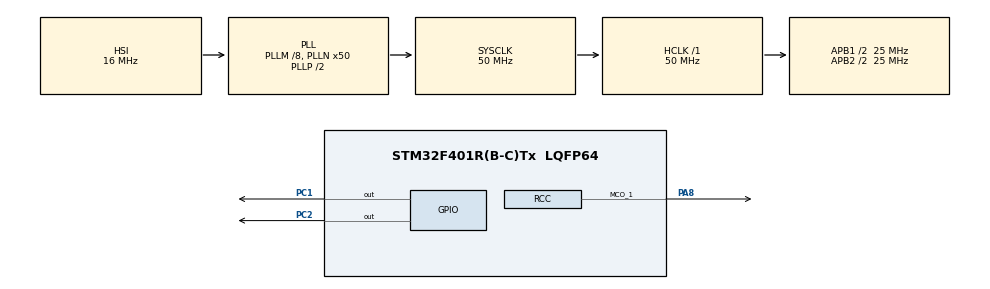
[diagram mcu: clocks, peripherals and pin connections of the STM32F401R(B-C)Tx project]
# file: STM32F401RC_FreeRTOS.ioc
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Mcu.Family=STM32F4
Mcu.Name=STM32F401R(B-C)Tx
Mcu.Package=LQFP64
NVIC.PriorityGroup=NVIC_PRIORITYGROUP_4
NVIC.TIM1_TRG_COM_TIM11_IRQn=true\:15\:0\:false\:false\:true\:false\:true\:true
NVIC.TIM1_UP_TIM10_IRQn=true\:0\:0\:false\:true\:true\:1\:true\:true\:true
NVIC.TimeBase=TIM1_TRG_COM_TIM11_IRQn
NVIC.TimeBaseIP=TIM11
PA8.Mode=Clock-out-1
PA8.Signal=RCC_MCO_1
PC1.GPIO_Speed=GPIO_SPEED_FREQ_VERY_HIGH
PC1.Signal=GPIO_Output
PC2.GPIO_Speed=GPIO_SPEED_FREQ_VERY_HIGH
PC2.Signal=GPIO_Output
PH0\ -\ OSC_IN.Mode=HSE-External-Oscillator
PH0\ -\ OSC_IN.Signal=RCC_OSC_IN
PH1\ -\ OSC_OUT.Mode=HSE-External-Oscillator
PH1\ -\ OSC_OUT.Signal=RCC_OSC_OUT
ProjectManager.HeapSize=0x200
ProjectManager.StackSize=0x400
ProjectManager.TargetToolchain=STM32CubeIDE
RCC.48MHZClocksFreq_Value=25000000
RCC.AHBFreq_Value=50000000
RCC.APB1CLKDivider=RCC_HCLK_DIV2
RCC.APB1Freq_Value=25000000
RCC.APB1TimFreq_Value=50000000
RCC.APB2CLKDivider=RCC_HCLK_DIV2
RCC.APB2Freq_Value=25000000
RCC.APB2TimFreq_Value=50000000
RCC.CortexFreq_Value=50000000
RCC.HCLKFreq_Value=50000000
RCC.HSE_VALUE=8000000
RCC.HSI_VALUE=16000000
RCC.LSE_VALUE=32768
RCC.PLLM=8
RCC.PLLN=50
RCC.RCC_MCO1Source=RCC_MCO1SOURCE_PLLCLK
RCC.RCC_MCODiv1=RCC_MCODIV_4
RCC.RCC_MCODiv2=RCC_MCODIV_5
RCC.SYSCLKFreq_VALUE=50000000
RCC.SYSCLKSource=RCC_SYSCLKSOURCE_PLLCLK
RCC.VCOOutputFreq_Value=100000000
TIM10.AutoReloadPreload=TIM_AUTORELOAD_PRELOAD_DISABLE
TIM10.Period=100+1
TIM10.Prescaler=50
VP_SYS_VS_tim11.Mode=TIM11
VP_TIM10_VS_ClockSourceINT.Mode=Enable_Timer
board=custom

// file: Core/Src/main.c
/* USER CODE BEGIN Header */
/**
  ******************************************************************************
  * @file           : main.c
  * @brief          : Main program body
  ******************************************************************************
  * @attention
  *
  * Copyright (c) 2026 STMicroelectronics.
  * All rights reserved.
  *
  * This software is licensed under terms that can be found in the LICENSE file
  * in the root directory of this software component.
  * If no LICENSE file comes with this software, it is provided AS-IS.
  *
  ******************************************************************************
  */
/* USER CODE END Header */
#include "main.h"

TIM_HandleTypeDef htim10;

void SystemClock_Config(void);
static void MX_GPIO_Init(void);
static void MX_TIM10_Init(void);
static void MX_NVIC_Init(void);

int main(void)
{

  /* MCU Configuration--------------------------------------------------------*/

  /* Reset of all peripherals, Initializes the Flash interface and the Systick. */
  HAL_Init();

  /* Configure the system clock */
  SystemClock_Config();

  /* Initialize all configured peripherals */
  MX_GPIO_Init();
  MX_TIM10_Init();

  /* Initialize interrupts */
  MX_NVIC_Init();

  /* Infinite loop */
  /* USER CODE BEGIN WHILE */
  while (1)
  {
	  HAL_GPIO_TogglePin(GPIOC, GPIO_PIN_1);
	  HAL_Delay(200);
    /* USER CODE END WHILE */

  }
}

void SystemClock_Config(void)
{
  RCC_OscInitTypeDef RCC_OscInitStruct = {0};
  RCC_ClkInitTypeDef RCC_ClkInitStruct = {0};

  /** Configure the main internal regulator output voltage
  */
  __HAL_RCC_PWR_CLK_ENABLE();
  __HAL_PWR_VOLTAGESCALING_CONFIG(PWR_REGULATOR_VOLTAGE_SCALE2);

  /** Initializes the RCC Oscillators according to the specified parameters
  * in the RCC_OscInitTypeDef structure.
  */
  RCC_OscInitStruct.OscillatorType = RCC_OSCILLATORTYPE_HSI;
  RCC_OscInitStruct.HSIState = RCC_HSI_ON;
  RCC_OscInitStruct.HSICalibrationValue = RCC_HSICALIBRATION_DEFAULT;
  RCC_OscInitStruct.PLL.PLLState = RCC_PLL_ON;
  RCC_OscInitStruct.PLL.PLLSource = RCC_PLLSOURCE_HSI;
  RCC_OscInitStruct.PLL.PLLM = 8;
  RCC_OscInitStruct.PLL.PLLN = 50;
  RCC_OscInitStruct.PLL.PLLP = RCC_PLLP_DIV2;
  RCC_OscInitStruct.PLL.PLLQ = 4;
  if (HAL_RCC_OscConfig(&RCC_OscInitStruct) != HAL_OK)
  {
    Error_Handler();
  }

  /** Initializes the CPU, AHB and APB buses clocks
  */
  RCC_ClkInitStruct.ClockType = RCC_CLOCKTYPE_HCLK|RCC_CLOCKTYPE_SYSCLK
                              |RCC_CLOCKTYPE_PCLK1|RCC_CLOCKTYPE_PCLK2;
  RCC_ClkInitStruct.SYSCLKSource = RCC_SYSCLKSOURCE_PLLCLK;
  RCC_ClkInitStruct.AHBCLKDivider = RCC_SYSCLK_DIV1;
  RCC_ClkInitStruct.APB1CLKDivider = RCC_HCLK_DIV2;
  RCC_ClkInitStruct.APB2CLKDivider = RCC_HCLK_DIV2;

  if (HAL_RCC_ClockConfig(&RCC_ClkInitStruct, FLASH_LATENCY_1) != HAL_OK)
  {
    Error_Handler();
  }
  HAL_RCC_MCOConfig(RCC_MCO1, RCC_MCO1SOURCE_PLLCLK, RCC_MCODIV_4);
}

/**
  * @brief NVIC Configuration.
  * @retval None
  */
static void MX_NVIC_Init(void)
{
  /* TIM1_UP_TIM10_IRQn interrupt configuration */
  HAL_NVIC_SetPriority(TIM1_UP_TIM10_IRQn, 0, 0);
  HAL_NVIC_EnableIRQ(TIM1_UP_TIM10_IRQn);
}

static void MX_TIM10_Init(void)
{

  htim10.Instance = TIM10;
  htim10.Init.Prescaler = 50;
  htim10.Init.CounterMode = TIM_COUNTERMODE_UP;
  htim10.Init.Period = 100+1;
  htim10.Init.ClockDivision = TIM_CLOCKDIVISION_DIV1;
  htim10.Init.AutoReloadPreload = TIM_AUTORELOAD_PRELOAD_DISABLE;
  if (HAL_TIM_Base_Init(&htim10) != HAL_OK)
  {
    Error_Handler();
  }
  /* USER CODE BEGIN TIM10_Init 2 */

  //HAL_TIM_IC_Start_IT(&htim10, TIM_CHANNEL_1);
  //HAL_TIM_OC_Start_IT(&htim10, TIM_CHANNEL_1);
  HAL_TIM_Base_Start_IT(&htim10);
  /* USER CODE END TIM10_Init 2 */

}

static void MX_GPIO_Init(void)
{
  GPIO_InitTypeDef GPIO_InitStruct = {0};

  /* GPIO Ports Clock Enable */
  __HAL_RCC_GPIOH_CLK_ENABLE();
  __HAL_RCC_GPIOC_CLK_ENABLE();
  __HAL_RCC_GPIOA_CLK_ENABLE();

  /*Configure GPIO pin Output Level */
  HAL_GPIO_WritePin(GPIOC, GPIO_PIN_1|GPIO_PIN_2, GPIO_PIN_RESET);

  /*Configure GPIO pins : PC1 PC2 */
  GPIO_InitStruct.Pin = GPIO_PIN_1|GPIO_PIN_2;
  GPIO_InitStruct.Mode = GPIO_MODE_OUTPUT_PP;
  GPIO_InitStruct.Pull = GPIO_NOPULL;
  GPIO_InitStruct.Speed = GPIO_SPEED_FREQ_VERY_HIGH;
  HAL_GPIO_Init(GPIOC, &GPIO_InitStruct);

  /*Configure GPIO pin : PA8 */
  GPIO_InitStruct.Pin = GPIO_PIN_8;
  GPIO_InitStruct.Mode = GPIO_MODE_AF_PP;
  GPIO_InitStruct.Pull = GPIO_NOPULL;
  GPIO_InitStruct.Speed = GPIO_SPEED_FREQ_LOW;
  GPIO_InitStruct.Alternate = GPIO_AF0_MCO;
  HAL_GPIO_Init(GPIOA, &GPIO_InitStruct);

}

/* USER CODE BEGIN 4 */

void HAL_TIM_IC_CaptureCallback(TIM_HandleTypeDef *Tim)
{
	//HAL_GPIO_TogglePin(GPIOC, GPIO_PIN_2);
	if(Tim->Instance == htim10.Instance)
	{
		//HAL_GPIO_TogglePin(GPIOC, GPIO_PIN_2);
	}
}

void HAL_TIM_OC_DelayElapsedCallback(TIM_HandleTypeDef *Tim)
{
	if(Tim->Instance == htim10.Instance)
	{
		HAL_GPIO_TogglePin(GPIOC, GPIO_PIN_2);
	}
}

/* USER CODE END 4 */

void HAL_TIM_PeriodElapsedCallback(TIM_HandleTypeDef *htim)
{
  if (htim->Instance == TIM11) {
    HAL_IncTick();
  }
  /* USER CODE BEGIN Callback 1 */
  if (htim->Instance == htim10.Instance) {
	  HAL_GPIO_TogglePin(GPIOC, GPIO_PIN_2);
  }
  /* USER CODE END Callback 1 */
}

void Error_Handler(void)
{
  __disable_irq();
  while (1)
  {
  }
}
